# pse84 register map
Vendor: Cypress Semiconductor; Series: PSE84; File version: 1.0
CPU: CM33 r0p1, little endian, MPU, FPU, VTOR, 3 interrupt priority bits
Registers are 32-bit, read-write, reset 0x0 unless marked. A register's access mark holds for its fields unless they carry their own. Offsets are from the block's base; [hi:lo] are bit positions; {n}, {i} and the like mark numbered series; 'fields as' and 'values as' point back to an identical list.

## SCB0 (part 2 of 2) — Serial Communications Block (SPI/UART/I2C)
Base 0x42990000
Same registers: SCB{n} {0x42980000+0x10000*n} (n=2..11), SCB1 0x42D00000
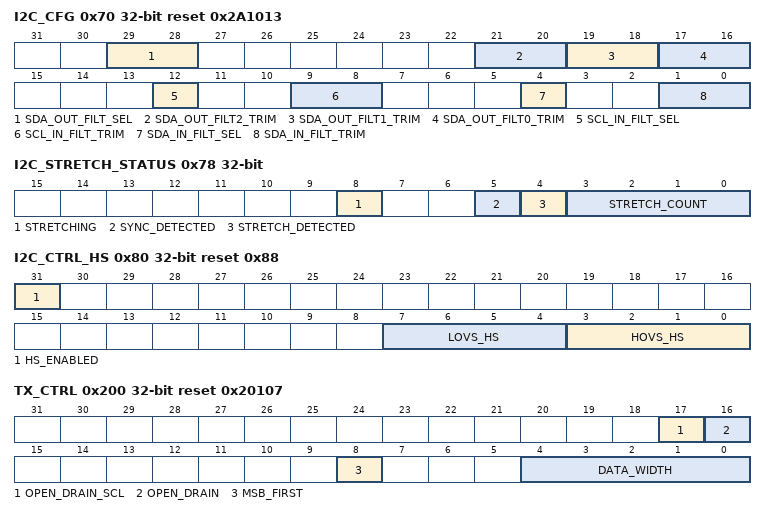
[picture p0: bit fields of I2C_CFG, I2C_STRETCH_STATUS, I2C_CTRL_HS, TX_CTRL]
0x70 I2C_CFG reset 0x2A1013 — I2C configuration
  [29:28] SDA_OUT_FILT_SEL — Selection of cumulative 'i2c_sda_out' filter delay: '0': 0 ns. '1', '2' or '3': 50 ns (filter 0 enabled). (NOTE: previous SCBs had the option of chossing between a 50ns, 100ns or 150ns filter. This option has been deprecated since mxscb.4.0 (CDT #251285)).
  [21:20] SDA_OUT_FILT2_TRIM — Trim bits for 'i2c_sda_out' 50 ns filter 2. for M0S8 platform, see s8i2cs BROS (001-59539) for more details on the trim bit values. For MXS40 platform, only the Least Significant Bit (LSB) is used, see s40iolib BROS (002-02511) for more details on the trim bit values.
  [19:18] SDA_OUT_FILT1_TRIM — Trim bits for 'i2c_sda_out' 50 ns filter 1. for M0S8 platform, see s8i2cs BROS (001-59539) for more details on the trim bit values. For MXS40 platform, only the Least Significant Bit (LSB) is used, see s40iolib BROS (002-02511) for more details on the trim bit values.
  [17:16] SDA_OUT_FILT0_TRIM — Trim bits for 'i2c_sda_out' 50 ns filter 0. for M0S8 platform, see s8i2cs BROS (001-59539) for more details on the trim bit values. For MXS40 platform, only the Least Significant Bit (LSB) is used, see s40iolib BROS (002-02511) for more details on the trim bit values.
  [12] SCL_IN_FILT_SEL — Selection of 'i2c_scl_in' filter delay: '0': 0 ns. '1: 50 ns (filter enabled).
  [9:8] SCL_IN_FILT_TRIM — Trim bits for 'i2c_scl_in' 50 ns filter. for M0S8 platform, see s8i2cs BROS (001-59539) for more details on the trim bit values. For MXS40 platform, only the Least Significant Bit (LSB) is used, see s40iolib BROS (002-02511) for more details on the trim bit values.
  [4] SDA_IN_FILT_SEL — Selection of 'i2c_sda_in' filter delay: '0': 0 ns. '1: 50 ns (filter enabled).
  [1:0] SDA_IN_FILT_TRIM — Trim bits for 'i2c_sda_in' 50 ns filter. for M0S8 platform, see s8i2cs BROS (001-59539) for more details on the trim bit values. For MXS40 platform, only the Least Significant Bit (LSB) is used, see s40iolib BROS (002-02511) for more details on the trim bit values.
0x74 I2C_STRETCH_CTRL — I2C stretch control
  [3:0] STRETCH_THRESHOLD — stretch threthold. Typically it is the SCL turaound delay (including IO cell delay, SCL rise time, analog filter delay), in number of clk_scb cycles. When STRETCH_COUNT is higher than this STRETCH_THRESHOLD, STRETCH_DETECTED will be set. STRETCH_DETECTED should be less than 'HOVS-2', HOVS means I2C_CTRL.HIGH_PHASE_OVS, or I2C_CTRL_HS.HOVS_HS.
0x78 I2C_STRETCH_STATUS ro
  [8] STRETCHING — I2C SCL is stretched by this block (DUT), for I2C master, this can happen when TX FIFO is empty, or RX_FIFO is full, or ACK/NACK is not decided, or RESTART/STOP is not decided. For I2C slave, this can heppend, TX FIFO is empty, or RX_FIFO is full, or ACK/NACK is not decided.
  [5] SYNC_DETECTED — synchronization detected. Set when I2C falling edge comes in earler than expected (suppressed by another I2C master during synchronization).
  [4] STRETCH_DETECTED — stretch detected. Set when I2C rising edge comes later than expected (suppressed by another master or slave), and STRETCH_COUNT is higher than STRETCH_THRESHOLD.
  [3:0] STRETCH_COUNT — stretch count. Started when I2C device start to drive high phase on internal SCL output signal, stalled when it detected high level on SCL input signal.
0x80 I2C_CTRL_HS reset 0x88 — I2C control for High-Speed mode
  [31] HS_ENABLED — 0': I2C Hs-mode is disabled, '1': I2C Hs-mode is enabled, when I2C Hs-mode is disabled and the IP is in I2C slave mode, hardware response to incoming Hs-mode transfers are undefined. When I2C Hs-mode is disabled and the IP is in I2C master mode, firmware should not generate Hs-mode transfers.
  [7:4] LOVS_HS — Serial I2C interface low phase oversampling factor for I2C Hs-mode. LOVS_HS + 1 peripheral clock periods constitute the low phase of a bit period. Hardware switch from I2C_CTRL.LOW_PHASE_OVS to this value automacitcally, at time t1; and switch back time tFS (when STOP detected). Firmware configure clk_scb frequency properly between t1 and tH.
  [3:0] HOVS_HS — Serial I2C interface high phase oversampling factor for I2C Hs-mode. HOVS_HS + 1 peripheral clock periods constitute the high phase of a bit period. Hardware switch from I2C_CTRL.HIGH_PHASE_OVS to this value automacitcally, at time t1; and switch back time tFS (when STOP detected). Firmware configure clk_scb frequency properly between t1 and tH.
0x200 TX_CTRL reset 0x20107 — Transmitter control
  [17] OPEN_DRAIN_SCL — Each IO cell 'xxx' has two associated IP output signals 'xxx_out_en' and 'xxx_out'. '0': Normal operation mode. Typically, this operation mode is used for IO cells that are connected to (board) wires/lines that are driven by a single IO cell. In this operation mode, for an IO cell 'xxx' that is used as an output, the 'xxx_out_en' output enable signal is typically constant '1' the 'xxx_out' output is the outputted value. In other words, in normal operation mode, the 'xxx_out' output is used to control the IO cell output value: 'xxx_out' is '0' to drive an IO cell output value of '0' and 'xxx_out' is '1' to drive an IO cell output value of '1'. '1': Open drain operation mode. Typically this operation mode is used for IO cells that are connected to (board) wires/lines that are driven by multiple IO cells (possibly on multiple chips). In this operation mode, for and IO cell 'xxx' that is used as an output, the 'xxx_out_en' output controls the outputted value. Typically, open drain operation mode drives low/'0' and the 'xxx_out' output is constant '1'. In other words, in open drain operation mode, the 'xxx_out_en' output is used to control the IO cell output value: in drive low/'0' mode: 'xxx_out_en' is '1' (drive enabled) to drive an IO cell output value of '0' and 'xxx_out_en' is '1' (drive disabled) to not drive an IO cell output value (another IO cell can drive the wire/line or a pull up results in a wire/line value '1'). this bit is applicable to I2C SCL only. I2C SDA always work in open-drain mode. this is not applicable to M0S8, which does not need special control in SCB for open-drain drive mode.
  [16] OPEN_DRAIN — Each IO cell 'xxx' has two associated IP output signals 'xxx_out_en' and 'xxx_out'. '0': Normal operation mode. Typically, this operation mode is used for IO cells that are connected to (board) wires/lines that are driven by a single IO cell. In this operation mode, for an IO cell 'xxx' that is used as an output, the 'xxx_out_en' output enable signal is typically constant '1' the 'xxx_out' output is the outputted value. In other words, in normal operation mode, the 'xxx_out' output is used to control the IO cell output value: 'xxx_out' is '0' to drive an IO cell output value of '0' and 'xxx_out' is '1' to drive an IO cell output value of '1'. '1': Open drain operation mode. Typically this operation mode is used for IO cells that are connected to (board) wires/lines that are driven by multiple IO cells (possibly on multiple chips). In this operation mode, for and IO cell 'xxx' that is used as an output, the 'xxx_out_en' output controls the outputted value. Typically, open drain operation mode drives low/'0' and the 'xxx_out' output is constant '1'. In other words, in open drain operation mode, the 'xxx_out_en' output is used to control the IO cell output value: in drive low/'0' mode: 'xxx_out_en' is '1' (drive enabled) to drive an IO cell output value of '0' and 'xxx_out_en' is '1' (drive disabled) to not drive an IO cell output value (another IO cell can drive the wire/line or a pull up results in a wire/line value '1'). The open drain mode is supported for: - UART mode, 'uart_tx' IO cell. - SPI mode, 'spi_miso' IO cell. this bit is not applicable to I2C mode, 'i2c_scl' and 'i2c_sda' IO cells.
  [8] MSB_FIRST — Least significant bit first ('0') or most significant bit first ('1'). For I2C, this field should be '1'.
  [4:0] DATA_WIDTH — Dataframe width, depending on CTRL.MEM_WIDTH. DATA_WIDTH + 1 is the amount of bits in a transmitted data frame. This number does not include start, parity and stop bits. For UART mode, the valid range is [3, 8]. For SPI, the valid range is [3, 31]. For I2C the only valid value is 7. In EZ mode (for both SPI and I2C), the only valid value is 7.
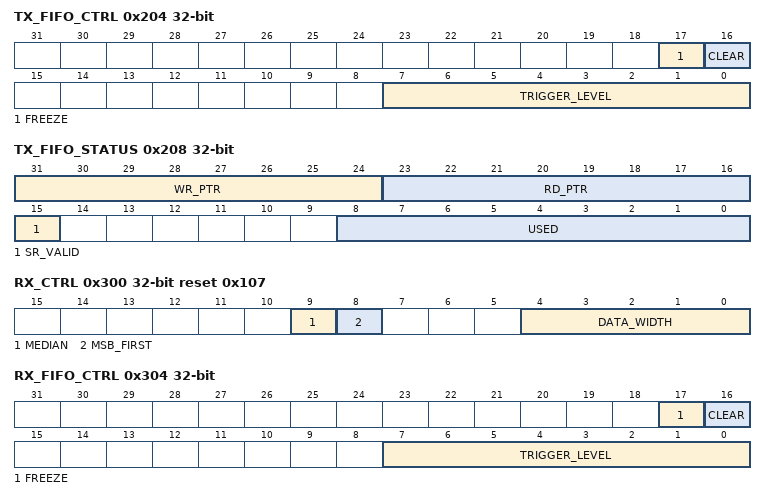
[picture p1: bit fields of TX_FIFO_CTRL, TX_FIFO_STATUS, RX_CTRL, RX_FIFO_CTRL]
0x204 TX_FIFO_CTRL — Transmitter FIFO control
  [17] FREEZE — When '1', hardware reads from the transmitter FIFO do not remove FIFO entries. Freeze will not advance the TX FIFO read pointer.
  [16] CLEAR — When '1', the transmitter FIFO and transmitter shift register are cleared/invalidated. Invalidation will last for as long as this field is '1'. If a quick clear/invalidation is required, the field should be set to '1' and be followed by a set to '0'. If a clear/invalidation is required for an extended time period, the field should be set to '1' during the complete time period.
  [7:0] TRIGGER_LEVEL — Trigger level. When the transmitter FIFO has less entries than the number of this field, a transmitter trigger event INTR_TX.TRIGGER is generated.
0x208 TX_FIFO_STATUS ro — Transmitter FIFO status
  [31:24] WR_PTR — FIFO write pointer: FIFO location at which a new data frame is written.
  [23:16] RD_PTR — FIFO read pointer: FIFO location from which a data frame is read by the hardware.
  [15] SR_VALID — Indicates whether the TX shift registers holds a valid data frame ('1') or not ('0'). The shift register can be considered the top of the TX FIFO (the data frame is not included in the USED field of the TX FIFO). The shift register is a working register and holds the data frame that is currently transmitted (when the protocol state machine is transmitting a data frame) or the data frame that is transmitted next (when the protocol state machine is not transmitting a data frame).
  [8:0] USED — Amount of entries in the transmitter FIFO. The value of this field ranges from 0 to FF_DATA_NR (EZ_DATA_NR/2).
0x240 TX_FIFO_WR wo — Transmitter FIFO write
  [31:0] DATA — Data frame written into the transmitter FIFO. Behavior is similar to that of a PUSH operation. Note that when CTRL.MEM_WIDTH is '0', only DATA[7:0] are used and when CTRL.MEM_WIDTH is '1', only DATA[15:0] are used. A write to a full TX FIFO sets INTR_TX.OVERFLOW to '1'.
0x300 RX_CTRL reset 0x107 — Receiver control
  [9] MEDIAN — Median filter. When '1', a digital 3 taps median filter is performed on input interface lines. This filter should reduce the susceptibility to errors. However, its requires higher oversampling values. For UART IrDA submode, this field should always be '1'.
  [8] MSB_FIRST — Least significant bit first ('0') or most significant bit first ('1'). For I2C, this field should be '1'.
  [4:0] DATA_WIDTH — Dataframe width, depending on CTRL.MEM_WIDTH. DATA_WIDTH + 1 is the expected amount of bits in received data frame. This number does not include start, parity and stop bits. For UART mode, the valid range is [3, 8]. For SPI, the valid range is [3, 31]. For I2C the only valid value is 7. In EZ mode (for both SPI and I2C), the only valid value is 7.
0x304 RX_FIFO_CTRL — Receiver FIFO control
  [17] FREEZE — When '1', hardware writes to the receiver FIFO have no effect. Freeze will not advance the RX FIFO write pointer.
  [16] CLEAR — When '1', the receiver FIFO and receiver shift register are cleared/invalidated. Invalidation will last for as long as this field is '1'. If a quick clear/invalidation is required, the field should be set to '1' and be followed by a set to '0'. If a clear/invalidation is required for an extended time period, the field should be set to '1' during the complete time period.
  [7:0] TRIGGER_LEVEL — Trigger level. When the receiver FIFO has more entries than the number of this field, a receiver trigger event INTR_RX.TRIGGER is generated.
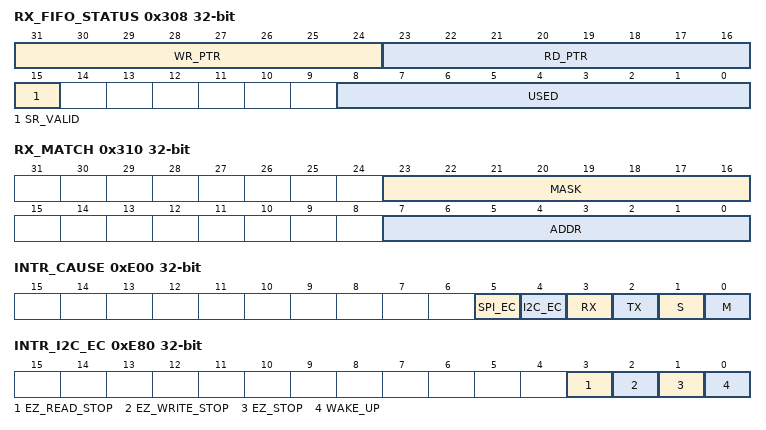
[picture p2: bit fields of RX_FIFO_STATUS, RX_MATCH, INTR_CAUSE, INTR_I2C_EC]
0x308 RX_FIFO_STATUS ro — Receiver FIFO status
  [31:24] WR_PTR — FIFO write pointer: FIFO location at which a new data frame is written by the hardware.
  [23:16] RD_PTR — FIFO read pointer: FIFO location from which a data frame is read.
  [15] SR_VALID — Indicates whether the RX shift registers holds a (partial) valid data frame ('1') or not ('0'). The shift register can be considered the bottom of the RX FIFO (the data frame is not included in the USED field of the RX FIFO). The shift register is a working register and holds the data frame that is currently being received (when the protocol state machine is receiving a data frame).
  [8:0] USED — Amount of entries in the receiver FIFO. The value of this field ranges from 0 to FF_DATA_NR (EZ_DATA_NR/2).
0x310 RX_MATCH — Slave address and mask
  [23:16] MASK — Slave device address mask. This field is a mask that specifies which of the ADDR field bits in the ADDR field take part in the matching of the slave address: MATCH = ((ADDR & MASK) == ('slave address' & MASK)).
  [7:0] ADDR — Slave device address. In UART multi-processor mode, all 8 bits are used. In I2C slave mode, only bits 7 down to 1 are used. This reflects the organization of the first transmitted byte in a I2C transfer: the first 7 bits represent the address of the addressed slave, and the last 1 bit is a read/write indicator ('0': write, '1': read).
0x340 RX_FIFO_RD ro reset not defined — Receiver FIFO read
  [31:0] DATA — Data read from the receiver FIFO. Reading a data frame will remove the data frame from the FIFO; i.e. behavior is similar to that of a POP operation. Note that when CTRL.MEM_WIDTH is '0', only DATA[7:0] are used and when CTRL.MEM_WIDTH is '1', only DATA[15:0] are used. This register has a side effect when read by software: a data frame is removed from the FIFO. This may be undesirable during debug; i.e. a read during debug should NOT have a side effect. To this end, the IP uses the AHB-Lite 'hmaster[0]' input signal. When this signal is '1' in the address cycle of a bus transfer, a read transfer will not have a side effect. As a result, a read from this register will not remove a data frame from the FIFO. As a result, a read from this register behaves as a read from the SCB_RX_FIFO_RD_SILENT register. A read from an empty RX FIFO sets INTR_RX.UNDERFLOW to '1'.
0x344 RX_FIFO_RD_SILENT ro reset not defined — Receiver FIFO read silent
  [31:0] DATA — Data read from the receiver FIFO. Reading a data frame will NOT remove the data frame from the FIFO; i.e. behavior is similar to that of a PEEK operation. Note that when CTRL.MEM_WIDTH is '0', only DATA[7:0] are used and when CTRL.MEM_WIDTH is '1', only DATA[15:0] are used A read from an empty RX FIFO sets INTR_RX.UNDERFLOW to '1'.
0xE00 INTR_CAUSE ro — Active clocked interrupt signal
  [5] SPI_EC — Externally clocked SPI interrupt active ('interrupt_spi_ec'): INTR_SPI_EC_MASKED != 0.
  [4] I2C_EC — Externally clock I2C interrupt active ('interrupt_i2c_ec'): INTR_I2C_EC_MASKED != 0.
  [3] RX — Receiver interrupt active ('interrupt_rx'): INTR_RX_MASKED != 0.
  [2] TX — Transmitter interrupt active ('interrupt_tx'): INTR_TX_MASKED != 0.
  [1] S — Slave interrupt active ('interrupt_slave'): INTR_S_MASKED != 0.
  [0] M — Master interrupt active ('interrupt_master'): INTR_M_MASKED != 0.
0xE80 INTR_I2C_EC — Externally clocked I2C interrupt request
  [3] EZ_READ_STOP — STOP detection after a read transfer occurred. Activated on the end of a read transfer (I2C STOP). This event is an indication that a buffer memory location has been read from. Only available for a slave request with an address match, in EZ and CMD_RESP modes, when EC_OP is '1'.
  [2] EZ_WRITE_STOP — STOP detection after a write transfer occurred. Activated on the end of a write transfer (I2C STOP). This event is an indication that a buffer memory location has been written to. For EZ mode: a transfer that only writes the base address does NOT activate this event. Only available for a slave request with an address match, in EZ and CMD_RESP modes, when EC_OP is '1'.
  [1] EZ_STOP — STOP detection. Activated on the end of a every transfer (I2C STOP). Only available for a slave request with an address match, in EZ and CMD_RESP modes, when EC_OP is '1'.
  [0] WAKE_UP — Wake up request. Active on incoming slave request (with address match). Only used when EC_AM is '1'.
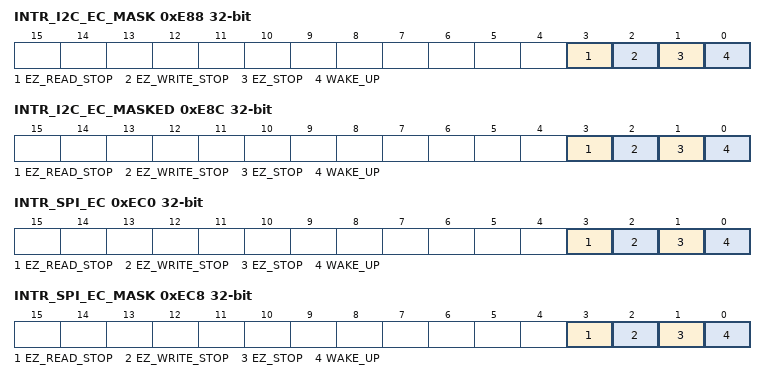
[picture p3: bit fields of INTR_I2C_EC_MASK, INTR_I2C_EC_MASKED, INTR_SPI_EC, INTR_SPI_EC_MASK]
0xE88 INTR_I2C_EC_MASK — Externally clocked I2C interrupt mask
  [3] EZ_READ_STOP — Mask bit for corresponding bit in interrupt request register.
  [2] EZ_WRITE_STOP — Mask bit for corresponding bit in interrupt request register.
  [1] EZ_STOP — Mask bit for corresponding bit in interrupt request register.
  [0] WAKE_UP — Mask bit for corresponding bit in interrupt request register.
0xE8C INTR_I2C_EC_MASKED ro — Externally clocked I2C interrupt masked
  [3] EZ_READ_STOP — Logical and of corresponding request and mask bits.
  [2] EZ_WRITE_STOP — Logical and of corresponding request and mask bits.
  [1] EZ_STOP — Logical and of corresponding request and mask bits.
  [0] WAKE_UP — Logical and of corresponding request and mask bits.
0xEC0 INTR_SPI_EC — Externally clocked SPI interrupt request
  [3] EZ_READ_STOP — STOP detection after a read transfer occurred. Activated on the end of a read transfer (SPI deselection). This event is an indication that a buffer memory location has been read from. Only used in EZ and CMD_RESP modes and when EC_OP is '1'.
  [2] EZ_WRITE_STOP — STOP detection after a write transfer occurred. Activated on the end of a write transfer (SPI deselection). This event is an indication that a buffer memory location has been written to. For EZ mode: a transfer that only writes the base address does NOT activate this event. Only used in EZ and CMD_RESP modes and when EC_OP is '1'.
  [1] EZ_STOP — STOP detection. Activated on the end of a every transfer (SPI deselection). Only available in EZ and CMD_RESP mode and when EC_OP is '1'.
  [0] WAKE_UP — Wake up request. Active on incoming slave request when externally clocked selection is '1'. Only used when EC_AM is '1'.
0xEC8 INTR_SPI_EC_MASK — Externally clocked SPI interrupt mask
  fields as INTR_I2C_EC_MASK
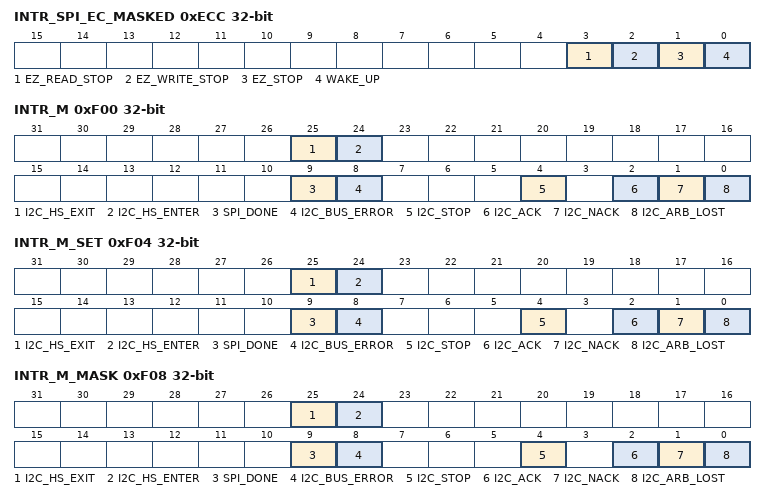
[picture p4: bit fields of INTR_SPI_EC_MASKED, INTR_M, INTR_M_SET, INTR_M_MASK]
0xECC INTR_SPI_EC_MASKED ro — Externally clocked SPI interrupt masked
  fields as INTR_I2C_EC_MASKED
0xF00 INTR_M — Master interrupt request
  [25] I2C_HS_EXIT — exited I2C Hs-mode, after STOP detection.
  [24] I2C_HS_ENTER — entered I2C Hs-mode, at time t1, SCL falling edge after 'START, 8-bit master code (0000_1XXX), NACK' sequence.
  [9] SPI_DONE — SPI master transfer done event: all data frames in the transmit FIFO are sent, the transmit FIFO is empty (both TX FIFO and transmit shifter register are empty), and SPI select output pin is deselected.
  [8] I2C_BUS_ERROR — I2C master bus error (unexpected detection of START or STOP condition).
  [4] I2C_STOP — I2C master STOP. Set to '1', when the master has transmitted a STOP.
  [2] I2C_ACK — I2C master acknowledgement. Set to '1', when the master receives a ACK (typically after the master transmitted the slave address or TX data).
  [1] I2C_NACK — I2C master negative acknowledgement. Set to '1', when the master receives a NACK (typically after the master transmitted the slave address or TX data).
  [0] I2C_ARB_LOST — I2C master lost arbitration: the value driven by the master on the SDA line is not the same as the value observed on the SDA line. The Firmware should clear the TX FIFO, to re-do this transfer.
0xF04 INTR_M_SET — Master interrupt set request
  [25] I2C_HS_EXIT — Write with '1' to set corresponding bit in interrupt request register.
  [24] I2C_HS_ENTER — Write with '1' to set corresponding bit in interrupt request register.
  [9] SPI_DONE — Write with '1' to set corresponding bit in interrupt request register.
  [8] I2C_BUS_ERROR — Write with '1' to set corresponding bit in interrupt request register.
  [4] I2C_STOP — Write with '1' to set corresponding bit in interrupt request register.
  [2] I2C_ACK — Write with '1' to set corresponding bit in interrupt request register.
  [1] I2C_NACK — Write with '1' to set corresponding bit in interrupt request register.
  [0] I2C_ARB_LOST — Write with '1' to set corresponding bit in interrupt request register.
0xF08 INTR_M_MASK — Master interrupt mask
  [25] I2C_HS_EXIT — Mask bit for corresponding bit in interrupt request register.
  [24] I2C_HS_ENTER — Mask bit for corresponding bit in interrupt request register.
  [9] SPI_DONE — Mask bit for corresponding bit in interrupt request register.
  [8] I2C_BUS_ERROR — Mask bit for corresponding bit in interrupt request register.
  [4] I2C_STOP — Mask bit for corresponding bit in interrupt request register.
  [2] I2C_ACK — Mask bit for corresponding bit in interrupt request register.
  [1] I2C_NACK — Mask bit for corresponding bit in interrupt request register.
  [0] I2C_ARB_LOST — Mask bit for corresponding bit in interrupt request register.
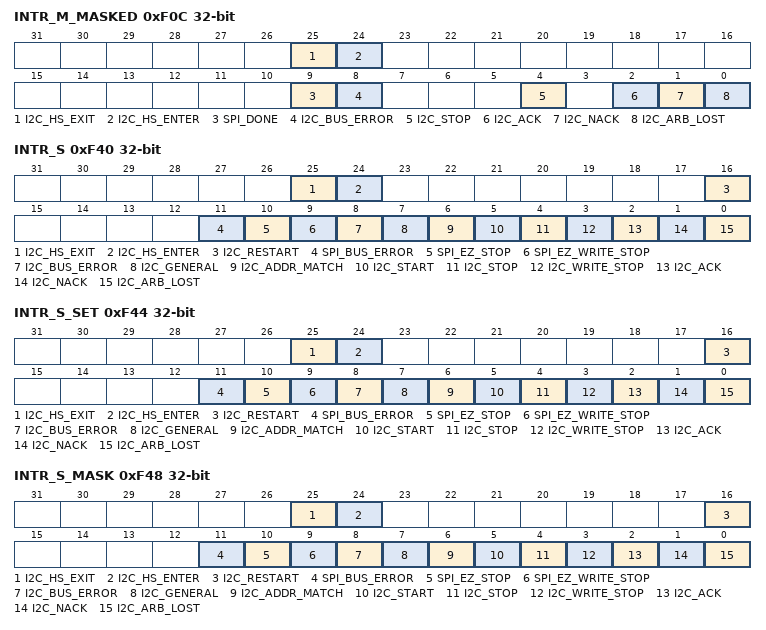
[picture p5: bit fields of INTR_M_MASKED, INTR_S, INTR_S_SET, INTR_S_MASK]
0xF0C INTR_M_MASKED ro — Master interrupt masked request
  [25] I2C_HS_EXIT — Logical and of corresponding request and mask bits.
  [24] I2C_HS_ENTER — Logical and of corresponding request and mask bits.
  [9] SPI_DONE — Logical and of corresponding request and mask bits.
  [8] I2C_BUS_ERROR — Logical and of corresponding request and mask bits.
  [4] I2C_STOP — Logical and of corresponding request and mask bits.
  [2] I2C_ACK — Logical and of corresponding request and mask bits.
  [1] I2C_NACK — Logical and of corresponding request and mask bits.
  [0] I2C_ARB_LOST — Logical and of corresponding request and mask bits.
0xF40 INTR_S — Slave interrupt request
  [25] I2C_HS_EXIT — exited I2C Hs-mode, after STOP detection.
  [24] I2C_HS_ENTER — entered I2C Hs-mode, at time t1, SCL falling edge after 'START, 8-bit master code (0000_1XXX), NACK' sequence.
  [16] I2C_RESTART — I2C slave RESTART received. Set to '1', when REPEATED START event is detected. In the case of externally clocked address matching (CTRL.EC_AM_MODE is '1') AND clock stretching is performed (I2C_CTRL.S_NOT_READY_ADDR_NACK is '0'), this field is NOT set. this is not applicable when address in previous transfer is master-code.
  [11] SPI_BUS_ERROR — SPI slave deselected at an unexpected time in the SPI transfer. The Firmware may decide to clear the TX and RX FIFOs in case of this error.
  [10] SPI_EZ_STOP — SPI slave deselected after any EZ SPI transfer occurred.
  [9] SPI_EZ_WRITE_STOP — SPI slave deselected after a write EZ SPI transfer occurred.
  [8] I2C_BUS_ERROR — I2C slave bus error (unexpected detection of START or STOP condition). This should not occur, it represents erroneous I2C bus behavior. In case of a bus error, the I2C slave state machine abort the ongoing transfer. The Firmware may decide to clear the TX and RX FIFOs in case of this error.
  [7] I2C_GENERAL — I2C slave general call address received. If CTRL.ADDR_ACCEPT, the received address 0x00 (including the R/W bit) is available in the RX FIFO. In the case of externally clocked address matching (CTRL.EC_AM_MODE is '1') and internally clocked operation (CTRL.EC_OP_MODE is '0'), this field is set when the event is detected.
  [6] I2C_ADDR_MATCH — I2C slave matching address received. If CTRL.ADDR_ACCEPT, the received address (including the R/W bit) is available in the RX FIFO. In the case of externally clocked address matching (CTRL.EC_AM_MODE is '1') and internally clocked operation (CTRL.EC_OP_MODE is '0'), this field is set when the event is detected.
  [5] I2C_START — I2C slave START received. Set to '1', when START or REPEATED START event is detected. In the case of externally clocked address matching (CTRL.EC_AM_MODE is '1') AND clock stretching is performed (I2C_CTRL.S_NOT_READY_ADDR_NACK is '0'), this field is NOT set. The Firmware should use INTR_S_EC.WAKE_UP, INTR_S.I2C_ADDR_MATCH and INTR_S.I2C_GENERAL.
  [4] I2C_STOP — I2C STOP event for I2C (read or write) transfer intended for this slave (address matching is performed). Set to '1', when STOP or REPEATED START event is detected. The REPEATED START event is included in this interrupt cause such that the I2C transfers separated by a REPEATED START can be distinguished and potentially treated separately by the Firmware. Note that the second I2C transfer (after a REPEATED START) may be to a different slave address. The event is detected on any I2C transfer intended for this slave. Note that a I2C address intended for the slave (address is matching) will result in a I2C_STOP event independent of whether the I2C address is ACK'd or NACK'd. this is not applicable when address in previous transfer is master-code.
  [3] I2C_WRITE_STOP — I2C STOP event for I2C write transfer intended for this slave (address matching is performed). Set to '1', when STOP or REPEATED START event is detected. The REPEATED START event is included in this interrupt cause such that the I2C transfers separated by a REPEATED START can be distinguished and potentially treated separately by the Firmware. Note that the second I2C transfer (after a REPEATED START) may be to a different slave address. In non EZ mode, the event is detected on any I2C write transfer intended for this slave. Note that a I2C write address intended for the slave (address is matching and a it is a write transfer) will result in a I2C_WRITE_STOP event independent of whether the I2C address is ACK'd or NACK'd. In EZ mode, the event is detected only on I2C write transfers that have EZ data written to the memory structure (an I2C write transfer that only communicates an I2C address and EZ address, will not result in this event being detected). this is not applicable when address in previous transfer is master-code.
  [2] I2C_ACK — I2C slave acknowledgement received. Set to '1', when the slave receives a ACK (typically after the slave transmitted TX data).
  [1] I2C_NACK — I2C slave negative acknowledgement received. Set to '1', when the slave receives a NACK (typically after the slave transmitted TX data).
  [0] I2C_ARB_LOST — I2C slave lost arbitration: the value driven on the SDA line is not the same as the value observed on the SDA line (while the SCL line is '1'). This should not occur, it represents erroneous I2C bus behavior. In case of lost arbitration, the I2C slave state machine abort the ongoing transfer. The Firmware should clear the TX FIFO, to re-do this transfer.
0xF44 INTR_S_SET — Slave interrupt set request
  [25] I2C_HS_EXIT — Write with '1' to set corresponding bit in interrupt request register.
  [24] I2C_HS_ENTER — Write with '1' to set corresponding bit in interrupt request register.
  [16] I2C_RESTART — Write with '1' to set corresponding bit in interrupt request register.
  [11] SPI_BUS_ERROR — Write with '1' to set corresponding bit in interrupt request register.
  [10] SPI_EZ_STOP — Write with '1' to set corresponding bit in interrupt request register.
  [9] SPI_EZ_WRITE_STOP — Write with '1' to set corresponding bit in interrupt request register.
  [8] I2C_BUS_ERROR — Write with '1' to set corresponding bit in interrupt request register.
  [7] I2C_GENERAL — Write with '1' to set corresponding bit in interrupt request register.
  [6] I2C_ADDR_MATCH — Write with '1' to set corresponding bit in interrupt request register.
  [5] I2C_START — Write with '1' to set corresponding bit in interrupt request register.
  [4] I2C_STOP — Write with '1' to set corresponding bit in interrupt request register.
  [3] I2C_WRITE_STOP — Write with '1' to set corresponding bit in interrupt request register.
  [2] I2C_ACK — Write with '1' to set corresponding bit in interrupt request register.
  [1] I2C_NACK — Write with '1' to set corresponding bit in interrupt request register.
  [0] I2C_ARB_LOST — Write with '1' to set corresponding bit in interrupt request register.
0xF48 INTR_S_MASK — Slave interrupt mask
  [25] I2C_HS_EXIT — Mask bit for corresponding bit in interrupt request register.
  [24] I2C_HS_ENTER — Mask bit for corresponding bit in interrupt request register.
  [16] I2C_RESTART — Mask bit for corresponding bit in interrupt request register.
  [11] SPI_BUS_ERROR — Mask bit for corresponding bit in interrupt request register.
  [10] SPI_EZ_STOP — Mask bit for corresponding bit in interrupt request register.
  [9] SPI_EZ_WRITE_STOP — Mask bit for corresponding bit in interrupt request register.
  [8] I2C_BUS_ERROR — Mask bit for corresponding bit in interrupt request register.
  [7] I2C_GENERAL — Mask bit for corresponding bit in interrupt request register.
  [6] I2C_ADDR_MATCH — Mask bit for corresponding bit in interrupt request register.
  [5] I2C_START — Mask bit for corresponding bit in interrupt request register.
  [4] I2C_STOP — Mask bit for corresponding bit in interrupt request register.
  [3] I2C_WRITE_STOP — Mask bit for corresponding bit in interrupt request register.
  [2] I2C_ACK — Mask bit for corresponding bit in interrupt request register.
  [1] I2C_NACK — Mask bit for corresponding bit in interrupt request register.
  [0] I2C_ARB_LOST — Mask bit for corresponding bit in interrupt request register.
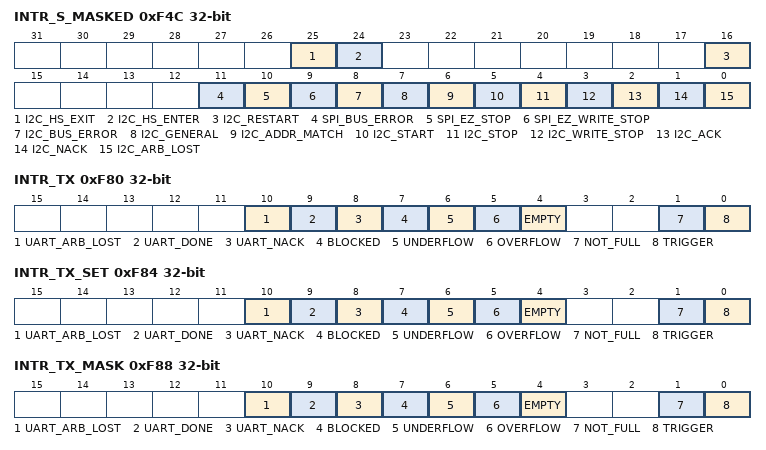
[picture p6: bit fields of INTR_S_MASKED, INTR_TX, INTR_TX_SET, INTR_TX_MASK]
0xF4C INTR_S_MASKED ro — Slave interrupt masked request
  [25] I2C_HS_EXIT — Logical and of corresponding request and mask bits.
  [24] I2C_HS_ENTER — Logical and of corresponding request and mask bits.
  [16] I2C_RESTART — Logical and of corresponding request and mask bits.
  [11] SPI_BUS_ERROR — Logical and of corresponding request and mask bits.
  [10] SPI_EZ_STOP — Logical and of corresponding request and mask bits.
  [9] SPI_EZ_WRITE_STOP — Logical and of corresponding request and mask bits.
  [8] I2C_BUS_ERROR — Logical and of corresponding request and mask bits.
  [7] I2C_GENERAL — Logical and of corresponding request and mask bits.
  [6] I2C_ADDR_MATCH — Logical and of corresponding request and mask bits.
  [5] I2C_START — Logical and of corresponding request and mask bits.
  [4] I2C_STOP — Logical and of corresponding request and mask bits.
  [3] I2C_WRITE_STOP — Logical and of corresponding request and mask bits.
  [2] I2C_ACK — Logical and of corresponding request and mask bits.
  [1] I2C_NACK — Logical and of corresponding request and mask bits.
  [0] I2C_ARB_LOST — Logical and of corresponding request and mask bits.
0xF80 INTR_TX — Transmitter interrupt request
  [10] UART_ARB_LOST — UART lost arbitration: the value driven on the TX line is not the same as the value observed on the RX line. This condition event is useful when transmitter and receiver share a TX/RX line. This is the case in LIN or SmartCard modes. Set to '1', when event is detected. Write with '1' to clear bit.
  [9] UART_DONE — UART transmitter done event. This happens when the IP is done transferring all data in the TX FIFO, and the last stop field is transmitted (both TX FIFO and transmit shifter register are empty). Set to '1', when event is detected. Write with '1' to clear bit.
  [8] UART_NACK — UART transmitter received a negative acknowledgement in SmartCard mode. Set to '1', when event is detected. Write with '1' to clear bit.
  [7] BLOCKED — AHB-Lite write transfer can not get access to the EZ memory (EZ data access), due to an externally clocked EZ access. This may happen when STATUS.EC_BUSY is '1'.
  [6] UNDERFLOW — Attempt to read from an empty TX FIFO. This happens when the IP is ready to transfer data and EMPTY is '1'. Only used in FIFO mode.
  [5] OVERFLOW — Attempt to write to a full TX FIFO. Only used in FIFO mode.
  [4] EMPTY — TX FIFO is empty; i.e. it has 0 entries. Only used in FIFO mode.
  [1] NOT_FULL — TX FIFO is not full. Dependent on CTRL.MEM_WIDTH: (FF_DATA_NR = EZ_DATA_NR/2) MEM_WIDTH is '0': # entries != FF_DATA_NR. MEM_WIDTH is '1': # entries != FF_DATA_NR/2. MEM_WIDTH is '2': # entries != FF_DATA_NR/4. Only used in FIFO mode.
  [0] TRIGGER — Less entries in the TX FIFO than the value specified by TX_FIFO_CTRL.TRIGGER_LEVEL. Only used in FIFO mode.
0xF84 INTR_TX_SET — Transmitter interrupt set request
  [10] UART_ARB_LOST — Write with '1' to set corresponding bit in interrupt request register.
  [9] UART_DONE — Write with '1' to set corresponding bit in interrupt request register.
  [8] UART_NACK — Write with '1' to set corresponding bit in interrupt request register.
  [7] BLOCKED — Write with '1' to set corresponding bit in interrupt request register.
  [6] UNDERFLOW — Write with '1' to set corresponding bit in interrupt request register.
  [5] OVERFLOW — Write with '1' to set corresponding bit in interrupt request register.
  [4] EMPTY — Write with '1' to set corresponding bit in interrupt request register.
  [1] NOT_FULL — Write with '1' to set corresponding bit in interrupt request register.
  [0] TRIGGER — Write with '1' to set corresponding bit in interrupt request register.
0xF88 INTR_TX_MASK — Transmitter interrupt mask
  [10] UART_ARB_LOST — Mask bit for corresponding bit in interrupt request register.
  [9] UART_DONE — Mask bit for corresponding bit in interrupt request register.
  [8] UART_NACK — Mask bit for corresponding bit in interrupt request register.
  [7] BLOCKED — Mask bit for corresponding bit in interrupt request register.
  [6] UNDERFLOW — Mask bit for corresponding bit in interrupt request register.
  [5] OVERFLOW — Mask bit for corresponding bit in interrupt request register.
  [4] EMPTY — Mask bit for corresponding bit in interrupt request register.
  [1] NOT_FULL — Mask bit for corresponding bit in interrupt request register.
  [0] TRIGGER — Mask bit for corresponding bit in interrupt request register.
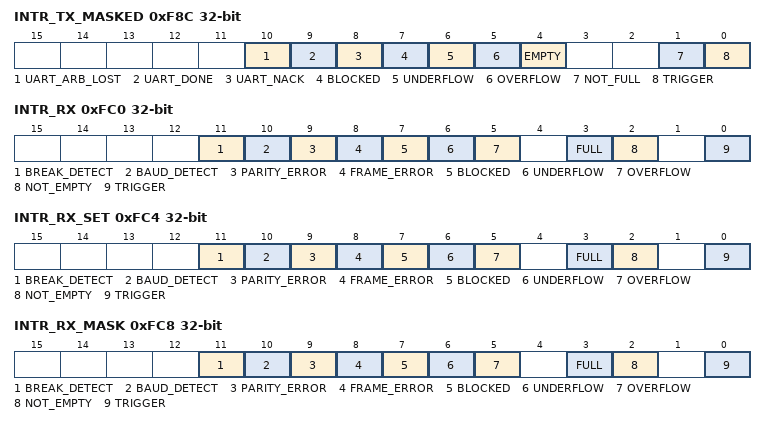
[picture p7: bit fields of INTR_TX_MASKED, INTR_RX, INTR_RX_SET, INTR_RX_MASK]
0xF8C INTR_TX_MASKED ro — Transmitter interrupt masked request
  [10] UART_ARB_LOST — Logical and of corresponding request and mask bits.
  [9] UART_DONE — Logical and of corresponding request and mask bits.
  [8] UART_NACK — Logical and of corresponding request and mask bits.
  [7] BLOCKED — Logical and of corresponding request and mask bits.
  [6] UNDERFLOW — Logical and of corresponding request and mask bits.
  [5] OVERFLOW — Logical and of corresponding request and mask bits.
  [4] EMPTY — Logical and of corresponding request and mask bits.
  [1] NOT_FULL — Logical and of corresponding request and mask bits.
  [0] TRIGGER — Logical and of corresponding request and mask bits.
0xFC0 INTR_RX — Receiver interrupt request
  [11] BREAK_DETECT — Break detection is successful: the line is '0' for UART_RX_CTRL.BREAK_WIDTH + 1 bit period. Can occur at any time to address unanticipated break fields; i.e. 'break-in-data' is supported. This feature is supported for the UART standard and LIN submodes. For the UART standard submodes, ongoing receipt of data frames is NOT affected; i.e. Firmware is expected to take the proper action. For the LIN submode, possible ongoing receipt of a data frame is stopped and the (partially) received data frame is dropped and baud rate detection is started. Set to '1', when event is detected. Write with '1' to clear bit.
  [10] BAUD_DETECT — LIN baudrate detection is completed. The receiver software uses the UART_RX_STATUS.BR_COUNTER value to set the right IP clock (from the programmable clock IP) to guarantee successful receipt of the first LIN data frame (Protected Identifier Field) after the synchronization byte. Set to '1', when event is detected. Write with '1' to clear bit.
  [9] PARITY_ERROR — Parity error in received data frame. Set to '1', when event is detected. Write with '1' to clear bit. If UART_RX_CTL.DROP_ON_PARITY_ERROR is '1', the received frame is dropped. If UART_RX_CTL.DROP_ON_PARITY_ERROR is '0', the received frame is send to the RX FIFO. In SmartCard submode, negatively acknowledged data frames generate a parity error. Note that Firmware can only identify the erroneous data frame in the RX FIFO if it is fast enough to read the data frame before the hardware writes a next data frame into the RX FIFO.
  [8] FRAME_ERROR — Frame error in received data frame. Set to '1', when event is detected. Write with '1' to clear bit. This can be either a start or stop bit(s) error: Start bit error: after the detection of the beginning of a start bit period (RX line changes from '1' to '0'), the middle of the start bit period is sampled erroneously (RX line is '1'). Note: a start bit error is detected BEFORE a data frame is received. Stop bit error: the RX line is sampled as '0', but a '1' was expected. Note: a stop bit error may result in failure to receive successive data frame(s). Note: a stop bit error is detected AFTER a data frame is received. A stop bit error is detected after a data frame is received, and the UART_RX_CTL.DROP_ON_FRAME_ERROR field specifies whether the received frame is dropped or send to the RX FIFO. If UART_RX_CTL.DROP_ON_FRAME_ERROR is '1', the received data frame is dropped. If UART_RX_CTL.DROP_ON_FRAME_ERROR is '0', the received data frame is send to the RX FIFO. Note that Firmware can only identify the erroneous data frame in the RX FIFO if it is fast enough to read the data frame before the hardware writes a next data frame into the RX FIFO; i.e. the RX FIFO does not have error flags to tag erroneous data frames.
  [7] BLOCKED — AHB-Lite read transfer can not get access to the EZ memory (EZ_DATA accesses), due to an externally clocked EZ access. This may happen when STATUS.EC_BUSY is '1'.
  [6] UNDERFLOW — Attempt to read from an empty RX FIFO. Only used in FIFO mode.
  [5] OVERFLOW — Attempt to write to a full RX FIFO. Note: in I2C mode, the OVERFLOW is set when a data frame is received and the RX FIFO is full, independent of whether it is ACK'd or NACK'd. Only used in FIFO mode.
  [3] FULL — RX FIFO is full. Note that received data frames are lost when the RX FIFO is full. Dependent on CTRL.MEM_WIDTH: (FF_DATA_NR = EZ_DATA_NR/2) MEM_WIDTH is '0': # entries == FF_DATA_NR. MEM_WIDTH is '1': # entries == FF_DATA_NR/2. MEM_WIDTH is '2': # entries == FF_DATA_NR/4. Only used in FIFO mode.
  [2] NOT_EMPTY — RX FIFO is not empty. Only used in FIFO mode.
  [0] TRIGGER — More entries in the RX FIFO than the value specified by RX_FIFO_CTRL.TRIGGER_LEVEL. Only used in FIFO mode.
0xFC4 INTR_RX_SET — Receiver interrupt set request
  [11] BREAK_DETECT — Write with '1' to set corresponding bit in interrupt status register.
  [10] BAUD_DETECT — Write with '1' to set corresponding bit in interrupt status register.
  [9] PARITY_ERROR — Write with '1' to set corresponding bit in interrupt status register.
  [8] FRAME_ERROR — Write with '1' to set corresponding bit in interrupt status register.
  [7] BLOCKED — Write with '1' to set corresponding bit in interrupt status register.
  [6] UNDERFLOW — Write with '1' to set corresponding bit in interrupt status register.
  [5] OVERFLOW — Write with '1' to set corresponding bit in interrupt status register.
  [3] FULL — Write with '1' to set corresponding bit in interrupt status register.
  [2] NOT_EMPTY — Write with '1' to set corresponding bit in interrupt status register.
  [0] TRIGGER — Write with '1' to set corresponding bit in interrupt request register.
0xFC8 INTR_RX_MASK — Receiver interrupt mask
  [11] BREAK_DETECT — Mask bit for corresponding bit in interrupt request register.
  [10] BAUD_DETECT — Mask bit for corresponding bit in interrupt request register.
  [9] PARITY_ERROR — Mask bit for corresponding bit in interrupt request register.
  [8] FRAME_ERROR — Mask bit for corresponding bit in interrupt request register.
  [7] BLOCKED — Mask bit for corresponding bit in interrupt request register.
  [6] UNDERFLOW — Mask bit for corresponding bit in interrupt request register.
  [5] OVERFLOW — Mask bit for corresponding bit in interrupt request register.
  [3] FULL — Mask bit for corresponding bit in interrupt request register.
  [2] NOT_EMPTY — Mask bit for corresponding bit in interrupt request register.
  [0] TRIGGER — Mask bit for corresponding bit in interrupt request register.
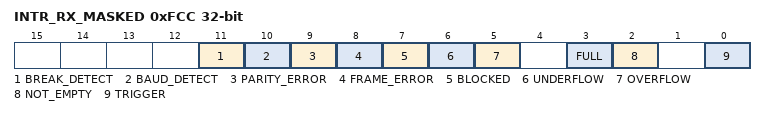
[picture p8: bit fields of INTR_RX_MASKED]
0xFCC INTR_RX_MASKED ro — Receiver interrupt masked request
  [11] BREAK_DETECT — Logical and of corresponding request and mask bits.
  [10] BAUD_DETECT — Logical and of corresponding request and mask bits.
  [9] PARITY_ERROR — Logical and of corresponding request and mask bits.
  [8] FRAME_ERROR — Logical and of corresponding request and mask bits.
  [7] BLOCKED — Logical and of corresponding request and mask bits.
  [6] UNDERFLOW — Logical and of corresponding request and mask bits.
  [5] OVERFLOW — Logical and of corresponding request and mask bits.
  [3] FULL — Logical and of corresponding request and mask bits.
  [2] NOT_EMPTY — Logical and of corresponding request and mask bits.
  [0] TRIGGER — Logical and of corresponding request and mask bits.
